# STM32U599 register map
File version: 0.2
CPU: CM33 r0p1, little endian, MPU, FPU, 4 interrupt priority bits
Registers are 32-bit, read-write, reset 0x0 unless marked. A register's access mark holds for its fields unless they carry their own. Offsets are from the block's base; [hi:lo] are bit positions; 'fields as' and 'values as' point back to an identical list.

## RTC — Real-time clock
Base 0x46007800
Same registers: SEC_RTC 0x56007800
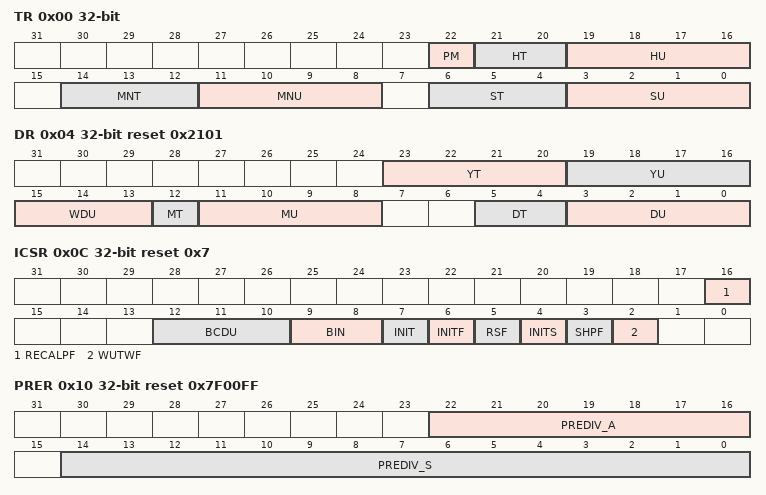
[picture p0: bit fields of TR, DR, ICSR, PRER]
0x00 TR — time register
  [22] PM — AM/PM notation
  [21:20] HT — Hour tens in BCD format
  [19:16] HU — Hour units in BCD format
  [14:12] MNT — Minute tens in BCD format
  [11:8] MNU — Minute units in BCD format
  [6:4] ST — Second tens in BCD format
  [3:0] SU — Second units in BCD format
0x04 DR reset 0x2101 — date register
  [23:20] YT — Year tens in BCD format
  [19:16] YU — Year units in BCD format
  [15:13] WDU — Week day units
  [12] MT — Month tens in BCD format
  [11:8] MU — Month units in BCD format
  [5:4] DT — Date tens in BCD format
  [3:0] DU — Date units in BCD format
0x08 SSR ro — RTC sub second register
  [31:0] SS
0x0C ICSR access per field reset 0x7 — RTC initialization control and status register
  [16] RECALPF ro — Recalibration pending Flag
  [12:10] BCDU rw
  [9:8] BIN rw
  [7] INIT rw — Initialization mode
  [6] INITF ro — Initialization flag
  [5] RSF rw — Registers synchronization flag
  [4] INITS ro — Initialization status flag
  [3] SHPF ro — Shift operation pending
  [2] WUTWF ro — Wakeup timer write flag
0x10 PRER reset 0x7F00FF — prescaler register
  [22:16] PREDIV_A — Asynchronous prescaler factor
  [14:0] PREDIV_S — Synchronous prescaler factor
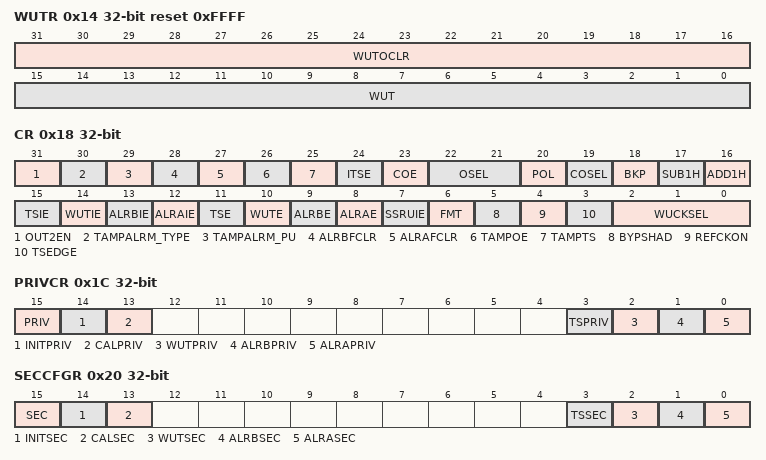
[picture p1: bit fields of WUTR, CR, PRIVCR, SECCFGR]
0x14 WUTR reset 0xFFFF — wakeup timer register
  [31:16] WUTOCLR
  [15:0] WUT — Wakeup auto-reload value bits
0x18 CR access per field — RTC control register
  [31] OUT2EN rw, [30] TAMPALRM_TYPE rw, [29] TAMPALRM_PU rw, [28] ALRBFCLR rw, [27] ALRAFCLR rw, [26] TAMPOE rw, [25] TAMPTS rw, [24] ITSE rw, [23] COE rw, [22:21] OSEL rw, [20] POL rw, [19] COSEL rw, [18] BKP rw, [17] SUB1H wo, [16] ADD1H wo, [15] TSIE rw, [14] WUTIE rw, [13] ALRBIE rw, [12] ALRAIE rw, [11] TSE rw, [10] WUTE rw, [9] ALRBE rw, [8] ALRAE rw, [7] SSRUIE rw, [6] FMT rw, [5] BYPSHAD rw, [4] REFCKON rw, [3] TSEDGE rw, [2:0] WUCKSEL rw
0x1C PRIVCR — RTC privilege mode control register
  [15] PRIV, [14] INITPRIV, [13] CALPRIV, [3] TSPRIV, [2] WUTPRIV, [1] ALRBPRIV, [0] ALRAPRIV
0x20 SECCFGR — RTC secure mode control register
  [15] SEC, [14] INITSEC, [13] CALSEC, [3] TSSEC, [2] WUTSEC, [1] ALRBSEC, [0] ALRASEC
0x24 WPR wo — write protection register
  [7:0] KEY — Write protection key
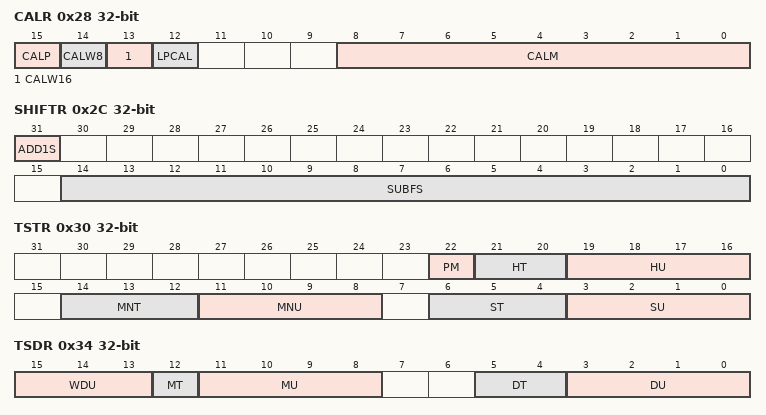
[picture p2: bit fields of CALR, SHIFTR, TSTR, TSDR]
0x28 CALR — calibration register
  [15] CALP — Increase frequency of RTC by 488.5 ppm
  [14] CALW8 — Use an 8-second calibration cycle period
  [13] CALW16 — Use a 16-second calibration cycle period
  [12] LPCAL
  [8:0] CALM — Calibration minus
0x2C SHIFTR wo — shift control register
  [31] ADD1S — Add one second
  [14:0] SUBFS — Subtract a fraction of a second
0x30 TSTR ro — time stamp time register
  fields as TR
0x34 TSDR ro — time stamp date register
  [15:13] WDU — Week day units
  [12] MT — Month tens in BCD format
  [11:8] MU — Month units in BCD format
  [5:4] DT — Date tens in BCD format
  [3:0] DU — Date units in BCD format
0x38 TSSSR ro — timestamp sub second register
  [31:0] SS — Sub second value
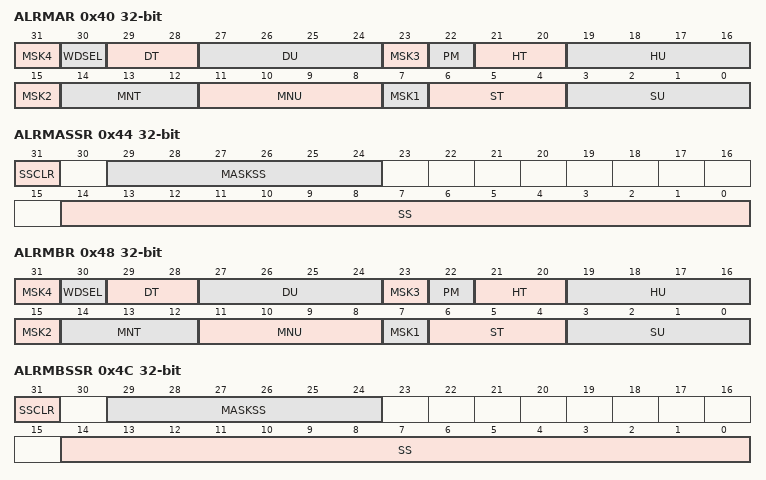
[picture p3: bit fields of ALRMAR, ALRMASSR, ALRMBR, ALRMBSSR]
0x40 ALRMAR — alarm A register
  [31] MSK4 — Alarm A date mask
  [30] WDSEL — Week day selection
  [29:28] DT — Date tens in BCD format
  [27:24] DU — Date units or day in BCD format
  [23] MSK3 — Alarm A hours mask
  [22] PM — AM/PM notation
  [21:20] HT — Hour tens in BCD format
  [19:16] HU — Hour units in BCD format
  [15] MSK2 — Alarm A minutes mask
  [14:12] MNT — Minute tens in BCD format
  [11:8] MNU — Minute units in BCD format
  [7] MSK1 — Alarm A seconds mask
  [6:4] ST — Second tens in BCD format
  [3:0] SU — Second units in BCD format
0x44 ALRMASSR — alarm A sub second register
  [31] SSCLR
  [29:24] MASKSS — Mask the most-significant bits starting at this bit
  [14:0] SS — Sub seconds value
0x48 ALRMBR — alarm B register
  [31] MSK4 — Alarm B date mask
  [30] WDSEL — Week day selection
  [29:28] DT — Date tens in BCD format
  [27:24] DU — Date units or day in BCD format
  [23] MSK3 — Alarm B hours mask
  [22] PM — AM/PM notation
  [21:20] HT — Hour tens in BCD format
  [19:16] HU — Hour units in BCD format
  [15] MSK2 — Alarm B minutes mask
  [14:12] MNT — Minute tens in BCD format
  [11:8] MNU — Minute units in BCD format
  [7] MSK1 — Alarm B seconds mask
  [6:4] ST — Second tens in BCD format
  [3:0] SU — Second units in BCD format
0x4C ALRMBSSR — alarm B sub second register
  fields as ALRMASSR
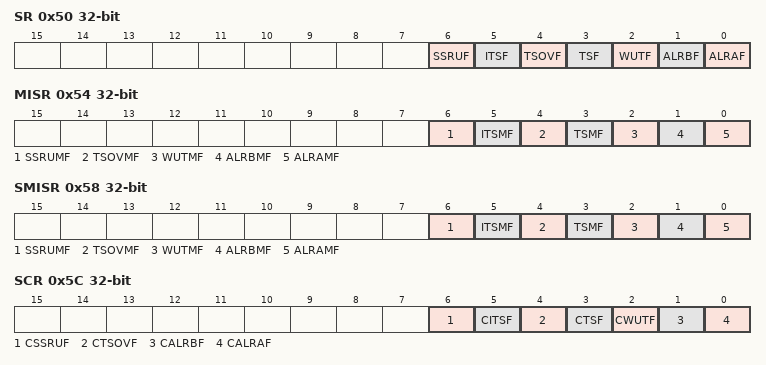
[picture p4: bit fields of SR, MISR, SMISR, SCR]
0x50 SR ro — RTC status register
  [6] SSRUF, [5] ITSF, [4] TSOVF, [3] TSF, [2] WUTF, [1] ALRBF, [0] ALRAF
0x54 MISR ro — RTC non-secure masked interrupt status register
  [6] SSRUMF, [5] ITSMF, [4] TSOVMF, [3] TSMF, [2] WUTMF, [1] ALRBMF, [0] ALRAMF
0x58 SMISR ro — RTC secure masked interrupt status register
  fields as MISR
0x5C SCR wo — RTC status clear register
  [6] CSSRUF, [5] CITSF, [4] CTSOVF, [3] CTSF, [2] CWUTF, [1] CALRBF, [0] CALRAF
0x70 ALRABINR — RTC alarm A binary mode register
  [31:0] SS — Synchronous counter alarm value in Binary mode
0x74 ALRBBINR — RTC alarm B binary mode register
  [31:0] SS — Synchronous counter alarm value in Binary mode
